AUTOSAR XML (schema 4-0-3)
standard types defined: uint8, Boolean, UInt16, UInt32, UInt8
package /AUTOSAR_Platform/DataConstrs
  range DC_Boolean: raw 0..1
  range DC_UInt16: raw 0..65535
  range DC_UInt8: raw 0..255
package /PATAC/Facility/DataTypes/Implementation
  compu method COMPU_Boolean: 0=FALSE, 1=TRUE
  unit NoUnit: factor-si-to-unit=1, offset-si-to-unit=0
package /PATAC/MSM/ComponentTypes
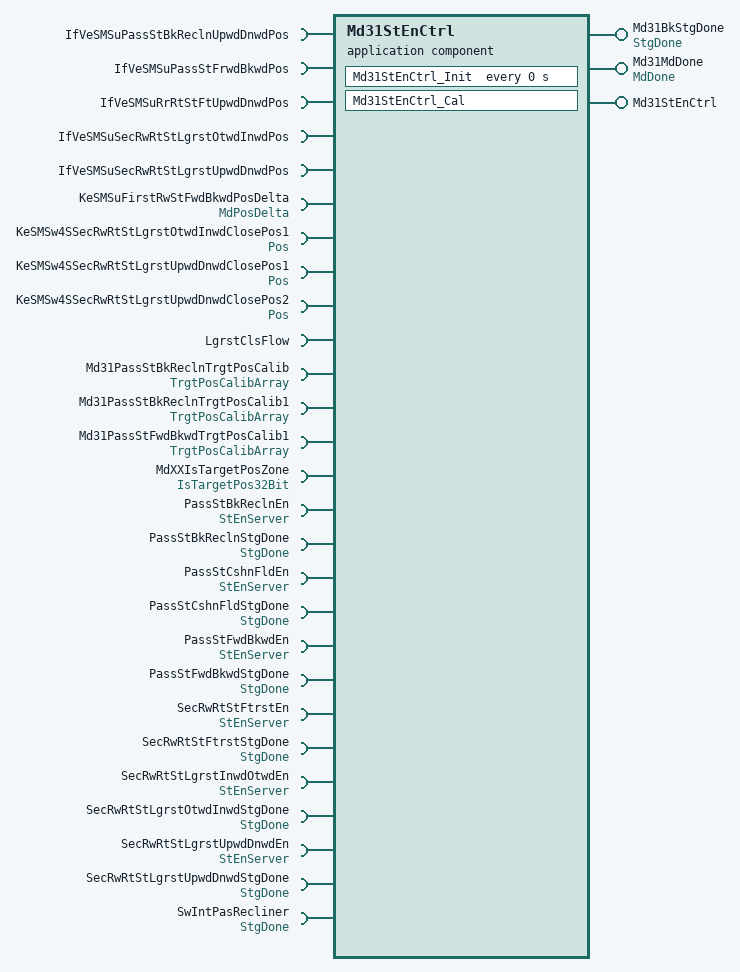
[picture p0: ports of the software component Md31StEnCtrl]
  application sw component type Md31StEnCtrl
    provide port Md31BkStgDone: nonqueued-sender-com-spec{data-element=StgDone/Val, init-value=0}, provided-interface=StgDone
    provide port Md31MdDone: nonqueued-sender-com-spec{data-element=MdDone/Val, init-value=0}, provided-interface=MdDone
    provide port Md31StEnCtrl: server-com-spec{operation=Md31StEnCtrl/Cal, queue-length=1}, provided-interface=Md31StEnCtrl
    27 x require port:
      IfVeSMSuPassStBkReclnUpwdDnwdPos: nonqueued-receiver-com-spec{data-element=IfVeSMSuPassStBkReclnUpwdDnwdPos/Val, filter=data-filter-type=ALWAYS, init-value=0}, required-interface=IfVeSMSuPassStBkReclnUpwdDnwdPos
      IfVeSMSuPassStFrwdBkwdPos: nonqueued-receiver-com-spec{data-element=IfVeSMSuPassStFrwdBkwdPos/Val, filter=data-filter-type=ALWAYS, init-value=0}, required-interface=IfVeSMSuPassStFrwdBkwdPos
      IfVeSMSuRrRtStFtUpwdDnwdPos: nonqueued-receiver-com-spec{data-element=IfVeSMSuRrRtStFtUpwdDnwdPos/Val, filter=data-filter-type=ALWAYS, init-value=0}, required-interface=IfVeSMSuRrRtStFtUpwdDnwdPos
      IfVeSMSuSecRwRtStLgrstOtwdInwdPos: nonqueued-receiver-com-spec{data-element=IfVeSMSuSecRwRtStLgrstOtwdInwdPos/Val, filter=data-filter-type=ALWAYS, init-value=0}, required-interface=IfVeSMSuSecRwRtStLgrstOtwdInwdPos
      IfVeSMSuSecRwRtStLgrstUpwdDnwdPos: nonqueued-receiver-com-spec{data-element=IfVeSMSuSecRwRtStLgrstUpwdDnwdPos/Val, filter=data-filter-type=ALWAYS, init-value=0}, required-interface=IfVeSMSuSecRwRtStLgrstUpwdDnwdPos
      KeSMSuFirstRwStFwdBkwdPosDelta: parameter-require-com-spec{init-value=150, parameter=MdPosDelta/Val}, required-interface=MdPosDelta
      KeSMSw4SSecRwRtStLgrstOtwdInwdClosePos1: parameter-require-com-spec{init-value=0, parameter=Pos/Val}, required-interface=Pos
      KeSMSw4SSecRwRtStLgrstUpwdDnwdClosePos1: parameter-require-com-spec{init-value=0, parameter=Pos/Val}, required-interface=Pos
      KeSMSw4SSecRwRtStLgrstUpwdDnwdClosePos2: parameter-require-com-spec{init-value=0, parameter=Pos/Val}, required-interface=Pos
      LgrstClsFlow: client-com-spec=LgrstClsFlow/Cal, required-interface=LgrstClsFlow
      Md31PassStBkReclnTrgtPosCalib: nonqueued-receiver-com-spec{data-element=TrgtPosArray, filter=data-filter-type=ALWAYS, init-value=[4095, 4095, 4095]}, required-interface=TrgtPosCalibArray
      Md31PassStBkReclnTrgtPosCalib1: nonqueued-receiver-com-spec{data-element=TrgtPosArray, filter=data-filter-type=ALWAYS, init-value=[4095, 4095, 4095]}, required-interface=TrgtPosCalibArray
      Md31PassStFwdBkwdTrgtPosCalib1: nonqueued-receiver-com-spec{data-element=TrgtPosArray, filter=data-filter-type=ALWAYS, init-value=[4095, 4095, 4095]}, required-interface=TrgtPosCalibArray
      MdXXIsTargetPosZone: nonqueued-receiver-com-spec{data-element=IsTargetPos32Bit/Val, filter=data-filter-type=ALWAYS, init-value=0}, required-interface=IsTargetPos32Bit
      PassStBkReclnEn: required-com-specs=[Clear, Get, Set], required-interface=StEnServer
      PassStBkReclnStgDone: nonqueued-receiver-com-spec{data-element=StgDone/Val, filter=data-filter-type=ALWAYS, init-value=0}, required-interface=StgDone
      PassStCshnFldEn: required-com-specs=[Clear, Get, Set], required-interface=StEnServer
      PassStCshnFldStgDone: nonqueued-receiver-com-spec{data-element=StgDone/Val, filter=data-filter-type=ALWAYS, init-value=0}, required-interface=StgDone
      PassStFwdBkwdEn: required-com-specs=[Clear, Get, Set], required-interface=StEnServer
      PassStFwdBkwdStgDone: nonqueued-receiver-com-spec{data-element=StgDone/Val, filter=data-filter-type=ALWAYS, init-value=0}, required-interface=StgDone
      SecRwRtStFtrstEn: required-com-specs=[Clear, Get, Set], required-interface=StEnServer
      SecRwRtStFtrstStgDone: nonqueued-receiver-com-spec{data-element=StgDone/Val, filter=data-filter-type=ALWAYS, init-value=0}, required-interface=StgDone
      SecRwRtStLgrstInwdOtwdEn: required-com-specs=[Clear, Get, Set], required-interface=StEnServer
      SecRwRtStLgrstOtwdInwdStgDone: nonqueued-receiver-com-spec{data-element=StgDone/Val, filter=data-filter-type=ALWAYS, init-value=0}, required-interface=StgDone
      SecRwRtStLgrstUpwdDnwdEn: required-com-specs=[Clear, Get, Set], required-interface=StEnServer
      SecRwRtStLgrstUpwdDnwdStgDone: nonqueued-receiver-com-spec{data-element=StgDone/Val, filter=data-filter-type=ALWAYS, init-value=0}, required-interface=StgDone
      SwIntPasRecliner: nonqueued-receiver-com-spec{data-element=StgDone/Val, filter=data-filter-type=ALWAYS, init-value=0}, required-interface=StgDone
    behavior Md31StEnCtrl_InternalBehavior
      operation invoked event OIT_Md31StEnCtrl_Cal_Md31StEnCtrl_Cal: start-on-event=Md31StEnCtrl_Cal, operation=Md31StEnCtrl.Cal
      timing event Md31StEnCtrl_InitEvent: start-on-event=Md31StEnCtrl_Init, period=0
      runnable Md31StEnCtrl_Cal
        data-receive-point-by-arguments:
          16 x access:
            REC_IfVeSMSuPassStBkReclnUpwdDnwdPos_Val: accessed-variable=IfVeSMSuPassStBkReclnUpwdDnwdPos.Val
            REC_IfVeSMSuPassStFrwdBkwdPos_Val: accessed-variable=IfVeSMSuPassStFrwdBkwdPos.Val
            REC_IfVeSMSuRrRtStFtUpwdDnwdPos_Val: accessed-variable=IfVeSMSuRrRtStFtUpwdDnwdPos.Val
            REC_IfVeSMSuSecRwRtStLgrstOtwdInwdPos_Val: accessed-variable=IfVeSMSuSecRwRtStLgrstOtwdInwdPos.Val
            REC_IfVeSMSuSecRwRtStLgrstUpwdDnwdPos_Val: accessed-variable=IfVeSMSuSecRwRtStLgrstUpwdDnwdPos.Val
            REC_Md31PassStBkReclnTrgtPosCalib_TrgtPosArray: accessed-variable=Md31PassStBkReclnTrgtPosCalib.TrgtPosArray
            REC_Md31PassStBkReclnTrgtPosCalib1_TrgtPosArray: accessed-variable=Md31PassStBkReclnTrgtPosCalib1.TrgtPosArray
            REC_Md31PassStFwdBkwdTrgtPosCalib1_TrgtPosArray: accessed-variable=Md31PassStFwdBkwdTrgtPosCalib1.TrgtPosArray
            REC_MdXXIsTargetPosZone_Val: accessed-variable=MdXXIsTargetPosZone.Val
            REC_PassStBkReclnStgDone_Val: accessed-variable=PassStBkReclnStgDone.Val
            REC_PassStCshnFldStgDone_Val: accessed-variable=PassStCshnFldStgDone.Val
            REC_PassStFwdBkwdStgDone_Val: accessed-variable=PassStFwdBkwdStgDone.Val
            REC_SecRwRtStFtrstStgDone_Val: accessed-variable=SecRwRtStFtrstStgDone.Val
            REC_SecRwRtStLgrstOtwdInwdStgDone_Val: accessed-variable=SecRwRtStLgrstOtwdInwdStgDone.Val
            REC_SecRwRtStLgrstUpwdDnwdStgDone_Val: accessed-variable=SecRwRtStLgrstUpwdDnwdStgDone.Val
            REC_SwIntPasRecliner_Val: accessed-variable=SwIntPasRecliner.Val
        data-send-points:
          access SEND_Md31BkStgDone_Val: accessed-variable=Md31BkStgDone.Val
          access SEND_Md31MdDone_Val: accessed-variable=Md31MdDone.Val
        4 x parameter access:
          PA_KeSMSuFirstRwStFwdBkwdPosDelta_Val: accessed-parameter=KeSMSuFirstRwStFwdBkwdPosDelta.Val
          PA_KeSMSw4SSecRwRtStLgrstOtwdInwdClosePos1_Val: accessed-parameter=KeSMSw4SSecRwRtStLgrstOtwdInwdClosePos1.Val
          PA_KeSMSw4SSecRwRtStLgrstUpwdDnwdClosePos1_Val: accessed-parameter=KeSMSw4SSecRwRtStLgrstUpwdDnwdClosePos1.Val
          PA_KeSMSw4SSecRwRtStLgrstUpwdDnwdClosePos2_Val: accessed-parameter=KeSMSw4SSecRwRtStLgrstUpwdDnwdClosePos2.Val
        19 x sync call, all with timeout=0:
          SC_LgrstClsFlow_Cal: operation=LgrstClsFlow.Cal
          SC_PassStBkReclnEn_Clear: operation=PassStBkReclnEn.Clear
          SC_PassStBkReclnEn_Get: operation=PassStBkReclnEn.Get
          SC_PassStBkReclnEn_Set: operation=PassStBkReclnEn.Set
          SC_PassStCshnFldEn_Clear: operation=PassStCshnFldEn.Clear
          SC_PassStCshnFldEn_Get: operation=PassStCshnFldEn.Get
          SC_PassStCshnFldEn_Set: operation=PassStCshnFldEn.Set
          SC_PassStFwdBkwdEn_Clear: operation=PassStFwdBkwdEn.Clear
          SC_PassStFwdBkwdEn_Get: operation=PassStFwdBkwdEn.Get
          SC_PassStFwdBkwdEn_Set: operation=PassStFwdBkwdEn.Set
          SC_SecRwRtStFtrstEn_Clear: operation=SecRwRtStFtrstEn.Clear
          SC_SecRwRtStFtrstEn_Get: operation=SecRwRtStFtrstEn.Get
          SC_SecRwRtStFtrstEn_Set: operation=SecRwRtStFtrstEn.Set
          SC_SecRwRtStLgrstInwdOtwdEn_Clear: operation=SecRwRtStLgrstInwdOtwdEn.Clear
          SC_SecRwRtStLgrstInwdOtwdEn_Get: operation=SecRwRtStLgrstInwdOtwdEn.Get
          SC_SecRwRtStLgrstInwdOtwdEn_Set: operation=SecRwRtStLgrstInwdOtwdEn.Set
          SC_SecRwRtStLgrstUpwdDnwdEn_Clear: operation=SecRwRtStLgrstUpwdDnwdEn.Clear
          SC_SecRwRtStLgrstUpwdDnwdEn_Get: operation=SecRwRtStLgrstUpwdDnwdEn.Get
          SC_SecRwRtStLgrstUpwdDnwdEn_Set: operation=SecRwRtStLgrstUpwdDnwdEn.Set
      runnable Md31StEnCtrl_Init
        4 x parameter access:
          PA_KeSMSuFirstRwStFwdBkwdPosDelta_Val: accessed-parameter=KeSMSuFirstRwStFwdBkwdPosDelta.Val
          PA_KeSMSw4SSecRwRtStLgrstOtwdInwdClosePos1_Val: accessed-parameter=KeSMSw4SSecRwRtStLgrstOtwdInwdClosePos1.Val
          PA_KeSMSw4SSecRwRtStLgrstUpwdDnwdClosePos1_Val: accessed-parameter=KeSMSw4SSecRwRtStLgrstUpwdDnwdClosePos1.Val
          PA_KeSMSw4SSecRwRtStLgrstUpwdDnwdClosePos2_Val: accessed-parameter=KeSMSw4SSecRwRtStLgrstUpwdDnwdClosePos2.Val
  swc implementation Md31StEnCtrl_Implementation: behavior=Md31StEnCtrl_InternalBehavior
    code-descriptors:
      code Default: artifact-descriptors=autosar-engineering-object={short-label=Default, category=SWSRC}
package /PATAC/MSM/ModeAdjust/CalPortInterface
  parameter interface MdPosDelta
    parameter data prototype Val: sw-calibration-access=READ-WRITE, type=UInt16
  parameter interface Pos
    parameter data prototype Val: sw-calibration-access=READ-WRITE, type=UInt16
package /PATAC/MSM/ModeAdjust/DataType
  impl type TrgtPosCalibArray: category=ARRAY, sw-calibration-access=READ-ONLY, type-emitter=RTE  # 0:pos 1:max 2:min
    element Element: array-size=3, array-size-semantics=FIXED-SIZE, implementation-data-type=UInt16, invalid-value=0
package /PATAC/MSM/ModeAdjust/PortInterface
  client server interface LgrstClsFlow
    operation Cal
      13 x arg, all with server-argument-impl-policy=USE-ARGUMENT-TYPE:
        LgrstUpwdDnwdPos: type=UInt16, direction=IN
        LgrstOtwdInwdPos: type=UInt16, direction=IN
        FtUpwdDnwdPos: type=UInt16, direction=IN
        CloseDnwdPos1: type=UInt16, direction=IN
        CloseDnwdPos2: type=UInt16, direction=IN
        CloseOtwdPos1: type=UInt16, direction=IN
        LgrstInwdStgDone: type=Boolean, direction=IN
        LgrstUpwdStgDone: type=Boolean, direction=IN
        FtrstStgDone: type=Boolean, direction=IN
        Failflg: type=Boolean, direction=OUT
        LgrstInwdOtwdEn: type=Boolean, direction=OUT
        LgrstUpwdDnwdEn: type=Boolean, direction=OUT
        FtrstEn: type=Boolean, direction=OUT
  client server interface Md31StEnCtrl
    operation Cal
      arg FirstTrig: type=Boolean, direction=IN, server-argument-impl-policy=USE-ARGUMENT-TYPE
  client server interface StEnServer
    operation Clear
      arg data: type=UInt8, direction=IN, server-argument-impl-policy=USE-ARGUMENT-TYPE
    operation Get
      arg data: type=UInt32, direction=OUT, server-argument-impl-policy=USE-ARGUMENT-TYPE
    operation Set
      arg data: type=UInt8, direction=IN, server-argument-impl-policy=USE-ARGUMENT-TYPE
  4 x sender receiver interface:
    IsTargetPos32Bit: invalidation-policy{data-element=IsTargetPos32Bit/Val, handle-invalid=DONT-INVALIDATE}
      data Val: type=UInt32
    MdDone: invalidation-policy{data-element=MdDone/Val, handle-invalid=DONT-INVALIDATE}
      data Val: type=UInt8
    StgDone: invalidation-policy{data-element=StgDone/Val, handle-invalid=DONT-INVALIDATE}
      data Val: type=Boolean
    TrgtPosCalibArray: invalidation-policy{data-element=TrgtPosArray, handle-invalid=DONT-INVALIDATE}
      data TrgtPosArray: type=TrgtPosCalibArray  # 0:Pos 1:Max 2:Min
package /PATAC/MSM/PortInterfaces
  5 x sender receiver interface:
    IfVeSMSuPassStBkReclnUpwdDnwdPos: invalidation-policy{data-element=IfVeSMSuPassStBkReclnUpwdDnwdPos/Val, handle-invalid=DONT-INVALIDATE}
      data Val: type=UInt16
    IfVeSMSuPassStFrwdBkwdPos: invalidation-policy{data-element=IfVeSMSuPassStFrwdBkwdPos/Val, handle-invalid=DONT-INVALIDATE}
      data Val: type=UInt16
    IfVeSMSuRrRtStFtUpwdDnwdPos: invalidation-policy{data-element=IfVeSMSuRrRtStFtUpwdDnwdPos/Val, handle-invalid=DONT-INVALIDATE}
      data Val: type=UInt16
    IfVeSMSuSecRwRtStLgrstOtwdInwdPos: invalidation-policy{data-element=IfVeSMSuSecRwRtStLgrstOtwdInwdPos/Val, handle-invalid=DONT-INVALIDATE}
      data Val: type=UInt16
    IfVeSMSuSecRwRtStLgrstUpwdDnwdPos: invalidation-policy{data-element=IfVeSMSuSecRwRtStLgrstUpwdDnwdPos/Val, handle-invalid=DONT-INVALIDATE}
      data Val: type=UInt16
